AUTOSAR XML (schema 4-0-3)
package /ComponentTypes
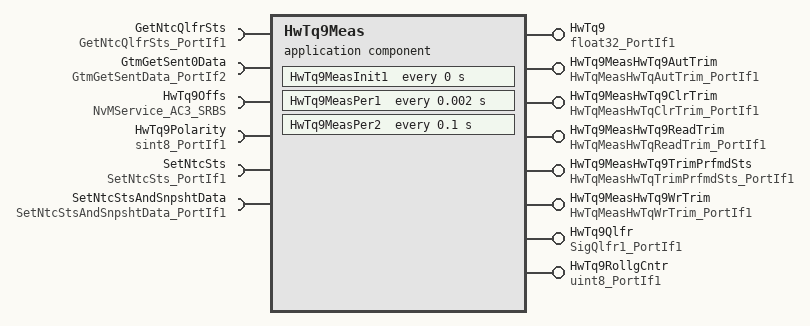
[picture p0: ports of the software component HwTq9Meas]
  application sw component type HwTq9Meas
    8 x provide port:
      HwTq9: nonqueued-sender-com-spec{data-element=Val, init-value=0}, provided-interface=float32_PortIf1
      HwTq9MeasHwTq9AutTrim: server-com-spec{operation=Oper, queue-length=1}, provided-interface=HwTqMeasHwTqAutTrim_PortIf1
      HwTq9MeasHwTq9ClrTrim: server-com-spec{operation=Oper, queue-length=1}, provided-interface=HwTqMeasHwTqClrTrim_PortIf1
      HwTq9MeasHwTq9ReadTrim: server-com-spec{operation=Oper, queue-length=1}, provided-interface=HwTqMeasHwTqReadTrim_PortIf1
      HwTq9MeasHwTq9TrimPrfmdSts: server-com-spec{operation=Oper, queue-length=1}, provided-interface=HwTqMeasHwTqTrimPrfmdSts_PortIf1
      HwTq9MeasHwTq9WrTrim: server-com-spec{operation=Oper, queue-length=1}, provided-interface=HwTqMeasHwTqWrTrim_PortIf1
      HwTq9Qlfr: nonqueued-sender-com-spec{data-element=Val, init-value=0}, provided-interface=SigQlfr1_PortIf1
      HwTq9RollgCntr: nonqueued-sender-com-spec{data-element=Val, init-value=0}, provided-interface=uint8_PortIf1
    6 x require port:
      GetNtcQlfrSts: client-com-spec=Oper, required-interface=GetNtcQlfrSts_PortIf1
      GtmGetSent0Data: client-com-spec=Oper, required-interface=GtmGetSentData_PortIf2
      HwTq9Offs: required-com-specs=[EraseBlock, GetErrorStatus, InvalidateNvBlock, ReadBlock, SetRamBlockStatus, WriteBlock], required-interface=NvMService_AC3_SRBS
      HwTq9Polarity: nonqueued-receiver-com-spec{data-element=Val, filter=data-filter-type=ALWAYS, init-value=1}, required-interface=sint8_PortIf1
      SetNtcSts: client-com-spec=Oper, required-interface=SetNtcSts_PortIf1
      SetNtcStsAndSnpshtData: client-com-spec=Oper, required-interface=SetNtcStsAndSnpshtData_PortIf1
    behavior HwTq9Meas_InternalBehavior
      ar-typed-per-instance-memorys:
        6 x data, all with sw-calibration-access=READ-ONLY:
          HwTq9Offs: type=HwTqOffsRec1
          HwTq9PrevHwTq: type=float32
          HwTq9RawDataBuf: type=Ary1D_u16_5
          HwTq9RollgCntrPrev: type=uint8
          HwTq9TiStamp: type=uint32
          HwTq9TiStampPrev: type=uint32
      5 x operation invoked event:
        OIT_HwTq9MeasHwTq9AutTrim_Oper_HwTq9MeasHwTq9AutTrim_Oper: start-on-event=HwTq9MeasHwTq9AutTrim_Oper, operation=HwTq9MeasHwTq9AutTrim.Oper
        OIT_HwTq9MeasHwTq9ClrTrim_Oper_HwTq9MeasHwTq9ClrTrim_Oper: start-on-event=HwTq9MeasHwTq9ClrTrim_Oper, operation=HwTq9MeasHwTq9ClrTrim.Oper
        OIT_HwTq9MeasHwTq9ReadTrim_Oper_HwTq9MeasHwTq9ReadTrim_Oper: start-on-event=HwTq9MeasHwTq9ReadTrim_Oper, operation=HwTq9MeasHwTq9ReadTrim.Oper
        OIT_HwTq9MeasHwTq9TrimPrfmdSts_Oper_HwTq9MeasHwTq9TrimPrfmdSts_Oper: start-on-event=HwTq9MeasHwTq9TrimPrfmdSts_Oper, operation=HwTq9MeasHwTq9TrimPrfmdSts.Oper
        OIT_HwTq9MeasHwTq9WrTrim_Oper_HwTq9MeasHwTq9WrTrim_Oper: start-on-event=HwTq9MeasHwTq9WrTrim_Oper, operation=HwTq9MeasHwTq9WrTrim.Oper
      timing event HwTq9Meas_InitEvent: start-on-event=HwTq9MeasInit1, period=0
      timing event TMT_HwTq9MeasPer1: start-on-event=HwTq9MeasPer1, period=0.002
      timing event TMT_HwTq9MeasPer2: start-on-event=HwTq9MeasPer2, period=0.1
      port-api-options:
        enable-take-address=false, indirect-api=false, port=GetNtcQlfrSts
        enable-take-address=false, indirect-api=false, port=GtmGetSent0Data
        enable-take-address=false, indirect-api=false, port=HwTq9
        enable-take-address=false, indirect-api=false, port=HwTq9MeasHwTq9AutTrim
        enable-take-address=false, indirect-api=false, port=HwTq9MeasHwTq9ClrTrim
        enable-take-address=false, indirect-api=false, port=HwTq9MeasHwTq9ReadTrim
        enable-take-address=false, indirect-api=false, port=HwTq9MeasHwTq9TrimPrfmdSts
        enable-take-address=false, indirect-api=false, port=HwTq9MeasHwTq9WrTrim
        enable-take-address=false, indirect-api=false, port=HwTq9Offs
        enable-take-address=false, indirect-api=false, port=HwTq9Polarity
        enable-take-address=false, indirect-api=false, port=HwTq9Qlfr
        enable-take-address=false, indirect-api=false, port=HwTq9RollgCntr
        enable-take-address=false, indirect-api=false, port=SetNtcSts
        enable-take-address=false, indirect-api=false, port=SetNtcStsAndSnpshtData
      8 x runnable:
        HwTq9MeasHwTq9AutTrim_Oper
          sync call SC_HwTq9Offs_SetRamBlockStatus: operation=HwTq9Offs.SetRamBlockStatus, timeout=0
        HwTq9MeasHwTq9ClrTrim_Oper
          sync call SC_HwTq9Offs_SetRamBlockStatus: operation=HwTq9Offs.SetRamBlockStatus, timeout=0
        HwTq9MeasHwTq9ReadTrim_Oper
        HwTq9MeasHwTq9TrimPrfmdSts_Oper
        HwTq9MeasHwTq9WrTrim_Oper
          sync call SC_HwTq9Offs_SetRamBlockStatus: operation=HwTq9Offs.SetRamBlockStatus, timeout=0
        HwTq9MeasInit1
          sync call SC_HwTq9Offs_GetErrorStatus: operation=HwTq9Offs.GetErrorStatus, timeout=0
        HwTq9MeasPer1
          data-receive-point-by-arguments:
            access REC_HwTq9Polarity_Val: accessed-variable=HwTq9Polarity.Val
          data-send-points:
            access SEND_HwTq9_Val: accessed-variable=HwTq9.Val
            access SEND_HwTq9Qlfr_Val: accessed-variable=HwTq9Qlfr.Val
            access SEND_HwTq9RollgCntr_Val: accessed-variable=HwTq9RollgCntr.Val
          sync call SC_GetNtcQlfrSts_Oper: operation=GetNtcQlfrSts.Oper, timeout=0
          sync call SC_GtmGetSent1Data_Oper: operation=GtmGetSent0Data.Oper, timeout=0
          sync call SC_SetNtcStsAndSnpshtData_Oper: operation=SetNtcStsAndSnpshtData.Oper, timeout=0
        HwTq9MeasPer2
          sync call SC_SetNtcSts_Oper: operation=SetNtcSts.Oper, timeout=0
      swc service dependency NvmHwTq9Offs: assigned-datas=role-based-data-assignment={role=ramBlock, used-data-element=HwTq9Offs}, assigned-ports=role-based-port-assignment={port-prototype=HwTq9Offs, role=NvMService_AC3_SRBS}
        service-needs:
          nv block needs NvmHwTq9Offs: n-data-sets=0, reliability=ERROR-DETECTION, resistant-to-changed-sw=true, restore-at-start=true, store-at-shutdown=true, writing-priority=LOW
  swc implementation HwTq9Meas_Implementation: behavior=HwTq9Meas_InternalBehavior
    code-descriptors:
      code Default: artifact-descriptors=autosar-engineering-object={short-label=Default, category=SWSRC}
